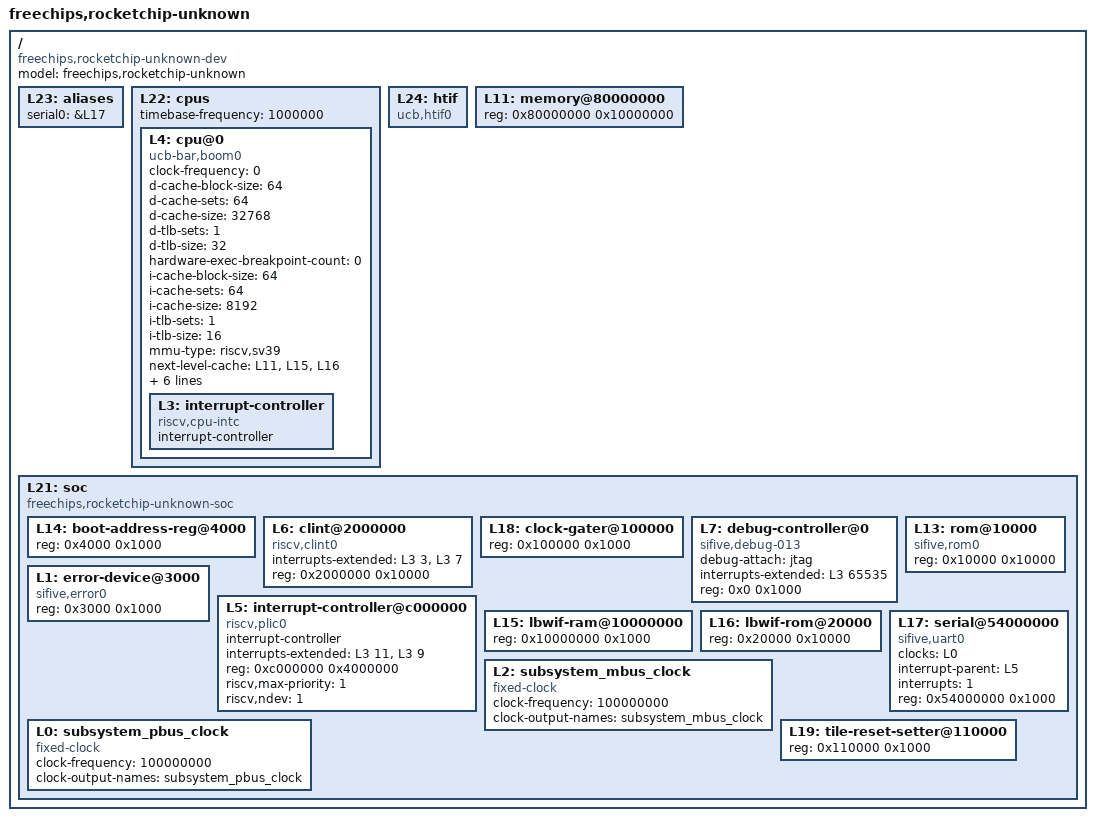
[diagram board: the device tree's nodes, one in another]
/dts-v1/;

/ {
	#address-cells = <1>;
	#size-cells = <1>;
	compatible = "freechips,rocketchip-unknown-dev";
	model = "freechips,rocketchip-unknown";
	L23: aliases {
		serial0 = &L17;
	};
	L22: cpus {
		#address-cells = <1>;
		#size-cells = <0>;
		timebase-frequency = <1000000>;
		L4: cpu@0 {
			clock-frequency = <0>;
			compatible = "ucb-bar,boom0", "riscv";
			d-cache-block-size = <64>;
			d-cache-sets = <64>;
			d-cache-size = <32768>;
			d-tlb-sets = <1>;
			d-tlb-size = <32>;
			device_type = "cpu";
			hardware-exec-breakpoint-count = <0>;
			i-cache-block-size = <64>;
			i-cache-sets = <64>;
			i-cache-size = <8192>;
			i-tlb-sets = <1>;
			i-tlb-size = <16>;
			mmu-type = "riscv,sv39";
			next-level-cache = <&L11 &L15 &L16>;
			reg = <0x0>;
			riscv,isa = "rv64imafdcZicsr_Zifencei_Zihpm";
			riscv,pmpgranularity = <4>;
			riscv,pmpregions = <8>;
			status = "okay";
			timebase-frequency = <1000000>;
			tlb-split;
			L3: interrupt-controller {
				#interrupt-cells = <1>;
				compatible = "riscv,cpu-intc";
				interrupt-controller;
			};
		};
	};
	L24: htif {
		compatible = "ucb,htif0";
	};
	L11: memory@80000000 {
		device_type = "memory";
		reg = <0x80000000 0x10000000>;
	};
	L21: soc {
		#address-cells = <1>;
		#size-cells = <1>;
		compatible = "freechips,rocketchip-unknown-soc", "simple-bus";
		ranges;
		L14: boot-address-reg@4000 {
			reg = <0x4000 0x1000>;
			reg-names = "control";
		};
		L6: clint@2000000 {
			compatible = "riscv,clint0";
			interrupts-extended = <&L3 3 &L3 7>;
			reg = <0x2000000 0x10000>;
			reg-names = "control";
		};
		L18: clock-gater@100000 {
			reg = <0x100000 0x1000>;
			reg-names = "control";
		};
		L7: debug-controller@0 {
			compatible = "sifive,debug-013", "riscv,debug-013";
			debug-attach = "jtag";
			interrupts-extended = <&L3 65535>;
			reg = <0x0 0x1000>;
			reg-names = "control";
		};
		L1: error-device@3000 {
			compatible = "sifive,error0";
			reg = <0x3000 0x1000>;
		};
		L5: interrupt-controller@c000000 {
			#interrupt-cells = <1>;
			compatible = "riscv,plic0";
			interrupt-controller;
			interrupts-extended = <&L3 11 &L3 9>;
			reg = <0xc000000 0x4000000>;
			reg-names = "control";
			riscv,max-priority = <1>;
			riscv,ndev = <1>;
		};
		L15: lbwif-ram@10000000 {
			reg = <0x10000000 0x1000>;
		};
		L16: lbwif-rom@20000 {
			reg = <0x20000 0x10000>;
		};
		L13: rom@10000 {
			compatible = "sifive,rom0";
			reg = <0x10000 0x10000>;
			reg-names = "mem";
		};
		L17: serial@54000000 {
			clocks = <&L0>;
			compatible = "sifive,uart0";
			interrupt-parent = <&L5>;
			interrupts = <1>;
			reg = <0x54000000 0x1000>;
			reg-names = "control";
		};
		L2: subsystem_mbus_clock {
			#clock-cells = <0>;
			clock-frequency = <100000000>;
			clock-output-names = "subsystem_mbus_clock";
			compatible = "fixed-clock";
		};
		L0: subsystem_pbus_clock {
			#clock-cells = <0>;
			clock-frequency = <100000000>;
			clock-output-names = "subsystem_pbus_clock";
			compatible = "fixed-clock";
		};
		L19: tile-reset-setter@110000 {
			reg = <0x110000 0x1000>;
			reg-names = "control";
		};
	};
};
